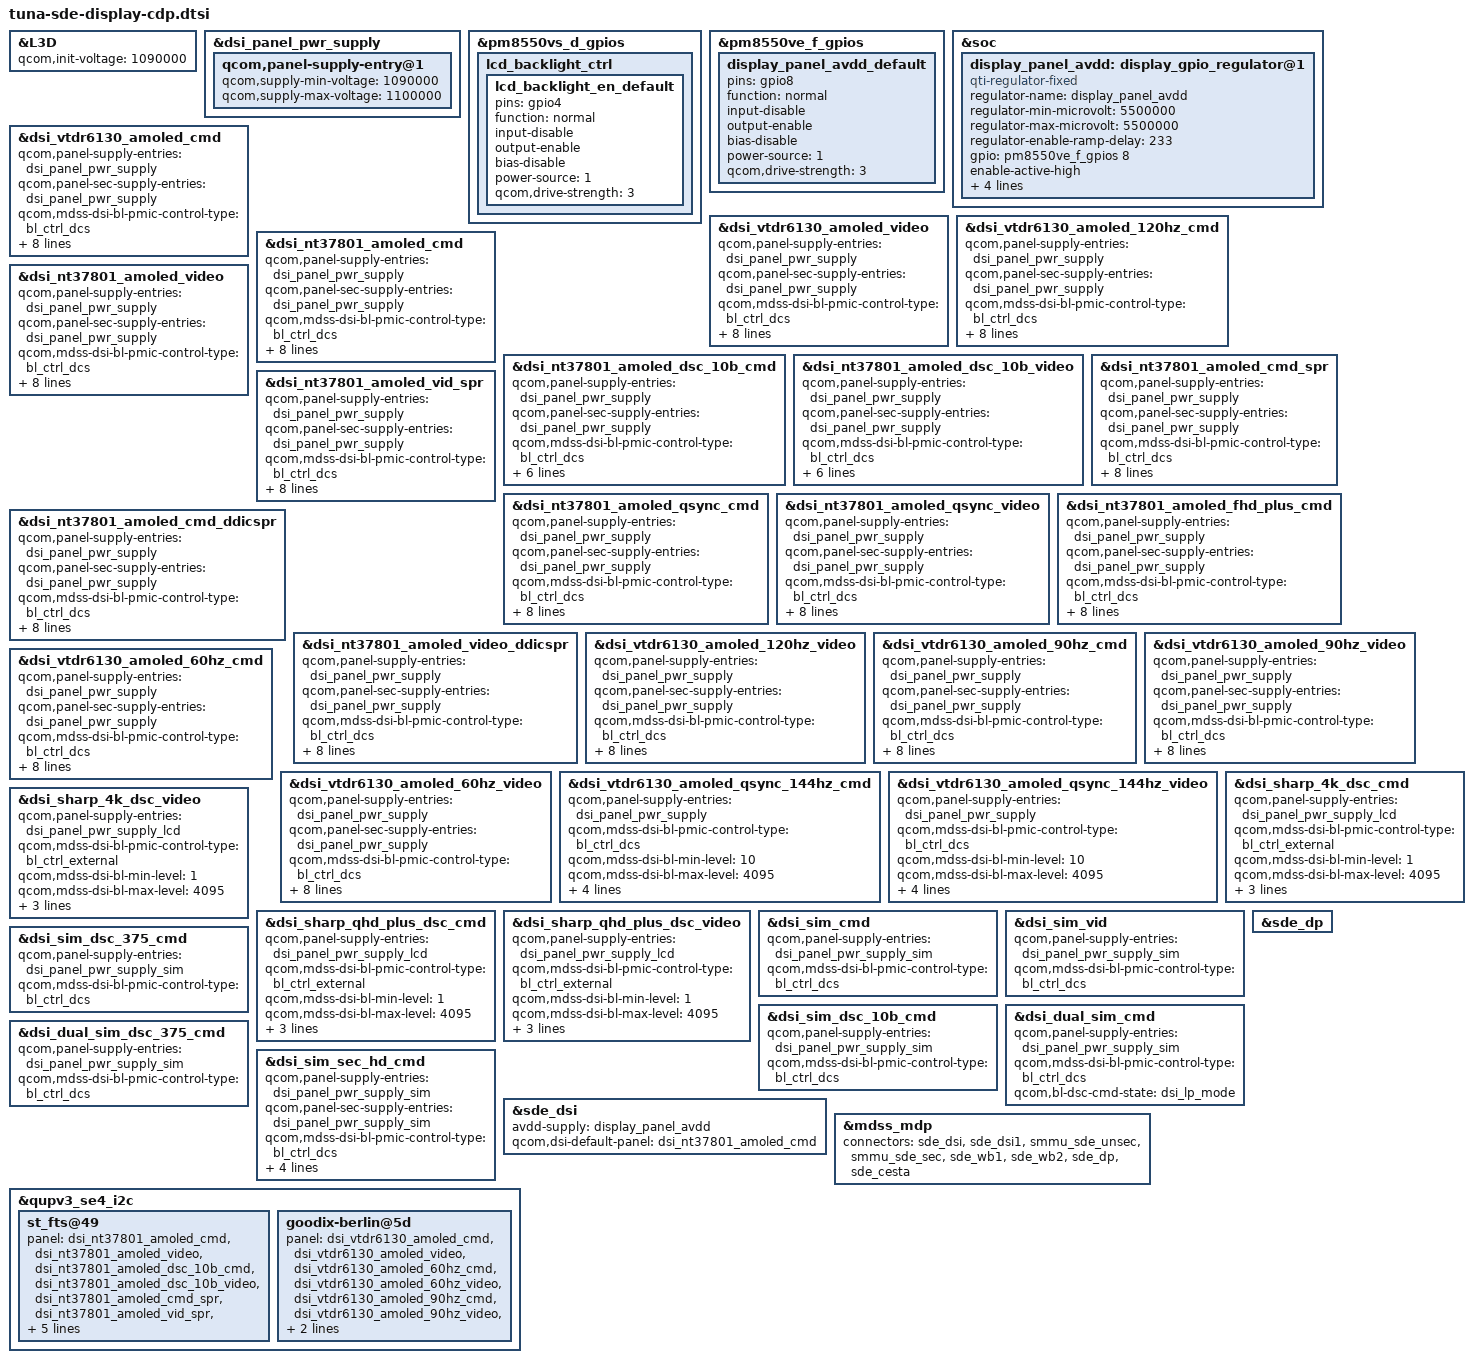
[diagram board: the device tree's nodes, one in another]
// SPDX-License-Identifier: BSD-3-Clause
/*
 * Copyright (c) Qualcomm Technologies, Inc. and/or its subsidiaries.
 */

#include "tuna-sde-display.dtsi"

&L3D {
	qcom,init-voltage = <1090000>;
};

&dsi_panel_pwr_supply {
	qcom,panel-supply-entry@1 {
		qcom,supply-min-voltage = <1090000>;
		qcom,supply-max-voltage = <1100000>;
	};
};

&pm8550vs_d_gpios {
	lcd_backlight_ctrl {
		lcd_backlight_en_default: lcd_backlight_en_default {
			pins = "gpio4";
			function = "normal";
			input-disable;
			output-enable;
			bias-disable;
			power-source = <1>;
			qcom,drive-strength = <3>;
		};
	};
};

&pm8550ve_f_gpios {
	display_panel_avdd_default: display_panel_avdd_default {
		pins = "gpio8";
		function = "normal";
		input-disable;
		output-enable;
		bias-disable;
		power-source = <1>;
		qcom,drive-strength = <3>;
	};
};

&soc {
	display_panel_avdd: display_gpio_regulator@1 {
		compatible = "qti-regulator-fixed";
		regulator-name = "display_panel_avdd";
		regulator-min-microvolt = <5500000>;
		regulator-max-microvolt = <5500000>;
		regulator-enable-ramp-delay = <233>;
		gpio = <&pm8550ve_f_gpios 8 0>;
		enable-active-high;
		regulator-boot-on;
		proxy-supply = <&display_panel_avdd>;
		qcom,proxy-consumer-enable;
		pinctrl-names = "default";
		pinctrl-0 = <&display_panel_avdd_default>;
	};
};

&dsi_vtdr6130_amoled_cmd {
	qcom,panel-supply-entries = <&dsi_panel_pwr_supply>;
	qcom,panel-sec-supply-entries = <&dsi_panel_pwr_supply>;
	qcom,mdss-dsi-bl-pmic-control-type = "bl_ctrl_dcs";
	qcom,mdss-dsi-sec-bl-pmic-control-type = "bl_ctrl_dcs";
	qcom,mdss-dsi-bl-min-level = <10>;
	qcom,mdss-dsi-bl-max-level = <4095>;
	qcom,mdss-brightness-max-level = <8191>;
	qcom,mdss-dsi-bl-inverted-dbv;
	qcom,platform-reset-gpio = <&tlmm 14 0>;
	qcom,platform-sec-reset-gpio = <&tlmm 126 0>;
};

&dsi_vtdr6130_amoled_video {
	qcom,panel-supply-entries = <&dsi_panel_pwr_supply>;
	qcom,panel-sec-supply-entries = <&dsi_panel_pwr_supply>;
	qcom,mdss-dsi-bl-pmic-control-type = "bl_ctrl_dcs";
	qcom,mdss-dsi-sec-bl-pmic-control-type = "bl_ctrl_dcs";
	qcom,mdss-dsi-bl-min-level = <10>;
	qcom,mdss-dsi-bl-max-level = <4095>;
	qcom,mdss-brightness-max-level = <8191>;
	qcom,mdss-dsi-bl-inverted-dbv;
	qcom,platform-reset-gpio = <&tlmm 14 0>;
	qcom,platform-sec-reset-gpio = <&tlmm 126 0>;
};

&dsi_vtdr6130_amoled_120hz_cmd {
	qcom,panel-supply-entries = <&dsi_panel_pwr_supply>;
	qcom,panel-sec-supply-entries = <&dsi_panel_pwr_supply>;
	qcom,mdss-dsi-bl-pmic-control-type = "bl_ctrl_dcs";
	qcom,mdss-dsi-sec-bl-pmic-control-type = "bl_ctrl_dcs";
	qcom,mdss-dsi-bl-min-level = <10>;
	qcom,mdss-dsi-bl-max-level = <4095>;
	qcom,mdss-brightness-max-level = <8191>;
	qcom,mdss-dsi-bl-inverted-dbv;
	qcom,platform-reset-gpio = <&tlmm 14 0>;
	qcom,platform-sec-reset-gpio = <&tlmm 126 0>;
};

&dsi_nt37801_amoled_cmd {
	qcom,panel-supply-entries = <&dsi_panel_pwr_supply>;
	qcom,panel-sec-supply-entries = <&dsi_panel_pwr_supply>;
	qcom,mdss-dsi-bl-pmic-control-type = "bl_ctrl_dcs";
	qcom,mdss-dsi-sec-bl-pmic-control-type = "bl_ctrl_dcs";
	qcom,mdss-dsi-bl-min-level = <10>;
	qcom,mdss-dsi-bl-max-level = <4095>;
	qcom,mdss-brightness-max-level = <8191>;
	qcom,mdss-dsi-bl-inverted-dbv;
	qcom,platform-reset-gpio = <&tlmm 14 0>;
	qcom,platform-sec-reset-gpio = <&tlmm 126 0>;
};

&dsi_nt37801_amoled_video {
	qcom,panel-supply-entries = <&dsi_panel_pwr_supply>;
	qcom,panel-sec-supply-entries = <&dsi_panel_pwr_supply>;
	qcom,mdss-dsi-bl-pmic-control-type = "bl_ctrl_dcs";
	qcom,mdss-dsi-sec-bl-pmic-control-type = "bl_ctrl_dcs";
	qcom,mdss-dsi-bl-min-level = <10>;
	qcom,mdss-dsi-bl-max-level = <4095>;
	qcom,mdss-brightness-max-level = <8191>;
	qcom,mdss-dsi-bl-inverted-dbv;
	qcom,platform-reset-gpio = <&tlmm 14 0>;
	qcom,platform-sec-reset-gpio = <&tlmm 126 0>;
};

&dsi_nt37801_amoled_dsc_10b_cmd {
	qcom,panel-supply-entries = <&dsi_panel_pwr_supply>;
	qcom,panel-sec-supply-entries = <&dsi_panel_pwr_supply>;
	qcom,mdss-dsi-bl-pmic-control-type = "bl_ctrl_dcs";
	qcom,mdss-dsi-bl-min-level = <10>;
	qcom,mdss-dsi-bl-max-level = <4095>;
	qcom,mdss-brightness-max-level = <8191>;
	qcom,mdss-dsi-bl-inverted-dbv;
	qcom,platform-reset-gpio = <&tlmm 14 0>;
	qcom,platform-sec-reset-gpio = <&tlmm 126 0>;
};

&dsi_nt37801_amoled_dsc_10b_video {
	qcom,panel-supply-entries = <&dsi_panel_pwr_supply>;
	qcom,panel-sec-supply-entries = <&dsi_panel_pwr_supply>;
	qcom,mdss-dsi-bl-pmic-control-type = "bl_ctrl_dcs";
	qcom,mdss-dsi-bl-min-level = <10>;
	qcom,mdss-dsi-bl-max-level = <4095>;
	qcom,mdss-brightness-max-level = <8191>;
	qcom,mdss-dsi-bl-inverted-dbv;
	qcom,platform-reset-gpio = <&tlmm 14 0>;
	qcom,platform-sec-reset-gpio = <&tlmm 126 0>;
};

&dsi_nt37801_amoled_cmd_spr {
	qcom,panel-supply-entries = <&dsi_panel_pwr_supply>;
	qcom,panel-sec-supply-entries = <&dsi_panel_pwr_supply>;
	qcom,mdss-dsi-bl-pmic-control-type = "bl_ctrl_dcs";
	qcom,mdss-dsi-sec-bl-pmic-control-type = "bl_ctrl_dcs";
	qcom,mdss-dsi-bl-min-level = <10>;
	qcom,mdss-dsi-bl-max-level = <4095>;
	qcom,mdss-brightness-max-level = <8191>;
	qcom,mdss-dsi-bl-inverted-dbv;
	qcom,platform-reset-gpio = <&tlmm 14 0>;
	qcom,platform-sec-reset-gpio = <&tlmm 126 0>;
};

&dsi_nt37801_amoled_vid_spr {
	qcom,panel-supply-entries = <&dsi_panel_pwr_supply>;
	qcom,panel-sec-supply-entries = <&dsi_panel_pwr_supply>;
	qcom,mdss-dsi-bl-pmic-control-type = "bl_ctrl_dcs";
	qcom,mdss-dsi-sec-bl-pmic-control-type = "bl_ctrl_dcs";
	qcom,mdss-dsi-bl-min-level = <10>;
	qcom,mdss-dsi-bl-max-level = <4095>;
	qcom,mdss-brightness-max-level = <8191>;
	qcom,mdss-dsi-bl-inverted-dbv;
	qcom,platform-reset-gpio = <&tlmm 14 0>;
	qcom,platform-sec-reset-gpio = <&tlmm 126 0>;
};

&dsi_nt37801_amoled_qsync_cmd {
	qcom,panel-supply-entries = <&dsi_panel_pwr_supply>;
	qcom,panel-sec-supply-entries = <&dsi_panel_pwr_supply>;
	qcom,mdss-dsi-bl-pmic-control-type = "bl_ctrl_dcs";
	qcom,mdss-dsi-sec-bl-pmic-control-type = "bl_ctrl_dcs";
	qcom,mdss-dsi-bl-min-level = <10>;
	qcom,mdss-dsi-bl-max-level = <4095>;
	qcom,mdss-brightness-max-level = <8191>;
	qcom,mdss-dsi-bl-inverted-dbv;
	qcom,platform-reset-gpio = <&tlmm 14 0>;
	qcom,platform-sec-reset-gpio = <&tlmm 126 0>;
};

&dsi_nt37801_amoled_qsync_video {
	qcom,panel-supply-entries = <&dsi_panel_pwr_supply>;
	qcom,panel-sec-supply-entries = <&dsi_panel_pwr_supply>;
	qcom,mdss-dsi-bl-pmic-control-type = "bl_ctrl_dcs";
	qcom,mdss-dsi-sec-bl-pmic-control-type = "bl_ctrl_dcs";
	qcom,mdss-dsi-bl-min-level = <10>;
	qcom,mdss-dsi-bl-max-level = <4095>;
	qcom,mdss-brightness-max-level = <8191>;
	qcom,mdss-dsi-bl-inverted-dbv;
	qcom,platform-reset-gpio = <&tlmm 14 0>;
	qcom,platform-sec-reset-gpio = <&tlmm 126 0>;
};

&dsi_nt37801_amoled_fhd_plus_cmd {
	qcom,panel-supply-entries = <&dsi_panel_pwr_supply>;
	qcom,panel-sec-supply-entries = <&dsi_panel_pwr_supply>;
	qcom,mdss-dsi-bl-pmic-control-type = "bl_ctrl_dcs";
	qcom,mdss-dsi-sec-bl-pmic-control-type = "bl_ctrl_dcs";
	qcom,mdss-dsi-bl-min-level = <10>;
	qcom,mdss-dsi-bl-max-level = <4095>;
	qcom,mdss-brightness-max-level = <8191>;
	qcom,mdss-dsi-bl-inverted-dbv;
	qcom,platform-reset-gpio = <&tlmm 14 0>;
	qcom,platform-sec-reset-gpio = <&tlmm 126 0>;
};

&dsi_nt37801_amoled_cmd_ddicspr {
	qcom,panel-supply-entries = <&dsi_panel_pwr_supply>;
	qcom,panel-sec-supply-entries = <&dsi_panel_pwr_supply>;
	qcom,mdss-dsi-bl-pmic-control-type = "bl_ctrl_dcs";
	qcom,mdss-dsi-sec-bl-pmic-control-type = "bl_ctrl_dcs";
	qcom,mdss-dsi-bl-min-level = <10>;
	qcom,mdss-dsi-bl-max-level = <4095>;
	qcom,mdss-brightness-max-level = <8191>;
	qcom,mdss-dsi-bl-inverted-dbv;
	qcom,platform-reset-gpio = <&tlmm 14 0>;
	qcom,platform-sec-reset-gpio = <&tlmm 126 0>;
};

&dsi_nt37801_amoled_video_ddicspr {
	qcom,panel-supply-entries = <&dsi_panel_pwr_supply>;
	qcom,panel-sec-supply-entries = <&dsi_panel_pwr_supply>;
	qcom,mdss-dsi-bl-pmic-control-type = "bl_ctrl_dcs";
	qcom,mdss-dsi-sec-bl-pmic-control-type = "bl_ctrl_dcs";
	qcom,mdss-dsi-bl-min-level = <10>;
	qcom,mdss-dsi-bl-max-level = <4095>;
	qcom,mdss-brightness-max-level = <8191>;
	qcom,mdss-dsi-bl-inverted-dbv;
	qcom,platform-reset-gpio = <&tlmm 14 0>;
	qcom,platform-sec-reset-gpio = <&tlmm 126 0>;
};

&dsi_vtdr6130_amoled_120hz_video {
	qcom,panel-supply-entries = <&dsi_panel_pwr_supply>;
	qcom,panel-sec-supply-entries = <&dsi_panel_pwr_supply>;
	qcom,mdss-dsi-bl-pmic-control-type = "bl_ctrl_dcs";
	qcom,mdss-dsi-sec-bl-pmic-control-type = "bl_ctrl_dcs";
	qcom,mdss-dsi-bl-min-level = <10>;
	qcom,mdss-dsi-bl-max-level = <4095>;
	qcom,mdss-brightness-max-level = <8191>;
	qcom,mdss-dsi-bl-inverted-dbv;
	qcom,platform-reset-gpio = <&tlmm 14 0>;
	qcom,platform-sec-reset-gpio = <&tlmm 126 0>;
};

&dsi_vtdr6130_amoled_90hz_cmd {
	qcom,panel-supply-entries = <&dsi_panel_pwr_supply>;
	qcom,panel-sec-supply-entries = <&dsi_panel_pwr_supply>;
	qcom,mdss-dsi-bl-pmic-control-type = "bl_ctrl_dcs";
	qcom,mdss-dsi-sec-bl-pmic-control-type = "bl_ctrl_dcs";
	qcom,mdss-dsi-bl-min-level = <10>;
	qcom,mdss-dsi-bl-max-level = <4095>;
	qcom,mdss-brightness-max-level = <8191>;
	qcom,mdss-dsi-bl-inverted-dbv;
	qcom,platform-reset-gpio = <&tlmm 14 0>;
	qcom,platform-sec-reset-gpio = <&tlmm 126 0>;
};

&dsi_vtdr6130_amoled_90hz_video {
	qcom,panel-supply-entries = <&dsi_panel_pwr_supply>;
	qcom,panel-sec-supply-entries = <&dsi_panel_pwr_supply>;
	qcom,mdss-dsi-bl-pmic-control-type = "bl_ctrl_dcs";
	qcom,mdss-dsi-sec-bl-pmic-control-type = "bl_ctrl_dcs";
	qcom,mdss-dsi-bl-min-level = <10>;
	qcom,mdss-dsi-bl-max-level = <4095>;
	qcom,mdss-brightness-max-level = <8191>;
	qcom,mdss-dsi-bl-inverted-dbv;
	qcom,platform-reset-gpio = <&tlmm 14 0>;
	qcom,platform-sec-reset-gpio = <&tlmm 126 0>;
};

&dsi_vtdr6130_amoled_60hz_cmd {
	qcom,panel-supply-entries = <&dsi_panel_pwr_supply>;
	qcom,panel-sec-supply-entries = <&dsi_panel_pwr_supply>;
	qcom,mdss-dsi-bl-pmic-control-type = "bl_ctrl_dcs";
	qcom,mdss-dsi-sec-bl-pmic-control-type = "bl_ctrl_dcs";
	qcom,mdss-dsi-bl-min-level = <10>;
	qcom,mdss-dsi-bl-max-level = <4095>;
	qcom,mdss-brightness-max-level = <8191>;
	qcom,mdss-dsi-bl-inverted-dbv;
	qcom,platform-reset-gpio = <&tlmm 14 0>;
	qcom,platform-sec-reset-gpio = <&tlmm 126 0>;
};

&dsi_vtdr6130_amoled_60hz_video {
	qcom,panel-supply-entries = <&dsi_panel_pwr_supply>;
	qcom,panel-sec-supply-entries = <&dsi_panel_pwr_supply>;
	qcom,mdss-dsi-bl-pmic-control-type = "bl_ctrl_dcs";
	qcom,mdss-dsi-sec-bl-pmic-control-type = "bl_ctrl_dcs";
	qcom,mdss-dsi-bl-min-level = <10>;
	qcom,mdss-dsi-bl-max-level = <4095>;
	qcom,mdss-brightness-max-level = <8191>;
	qcom,mdss-dsi-bl-inverted-dbv;
	qcom,platform-reset-gpio = <&tlmm 14 0>;
	qcom,platform-sec-reset-gpio = <&tlmm 126 0>;
};

&dsi_vtdr6130_amoled_qsync_144hz_cmd {
	qcom,panel-supply-entries = <&dsi_panel_pwr_supply>;
	qcom,mdss-dsi-bl-pmic-control-type = "bl_ctrl_dcs";
	qcom,mdss-dsi-bl-min-level = <10>;
	qcom,mdss-dsi-bl-max-level = <4095>;
	qcom,mdss-brightness-max-level = <8191>;
	qcom,mdss-dsi-bl-inverted-dbv;
	qcom,platform-reset-gpio = <&tlmm 14 0>;
	qcom,platform-sec-reset-gpio = <&tlmm 126 0>;
};

&dsi_vtdr6130_amoled_qsync_144hz_video {
	qcom,panel-supply-entries = <&dsi_panel_pwr_supply>;
	qcom,mdss-dsi-bl-pmic-control-type = "bl_ctrl_dcs";
	qcom,mdss-dsi-bl-min-level = <10>;
	qcom,mdss-dsi-bl-max-level = <4095>;
	qcom,mdss-brightness-max-level = <8191>;
	qcom,mdss-dsi-bl-inverted-dbv;
	qcom,platform-reset-gpio = <&tlmm 14 0>;
	qcom,platform-sec-reset-gpio = <&tlmm 126 0>;
};

&dsi_sharp_4k_dsc_cmd {
	qcom,panel-supply-entries = <&dsi_panel_pwr_supply_lcd>;
	qcom,mdss-dsi-bl-pmic-control-type = "bl_ctrl_external";
	qcom,mdss-dsi-bl-min-level = <1>;
	qcom,mdss-dsi-bl-max-level = <4095>;
	qcom,platform-reset-gpio = <&tlmm 14 0>;
	qcom,platform-bklight-en-gpio = <&pm8550vs_d_gpios 4 0>;
};

&dsi_sharp_4k_dsc_video {
	qcom,panel-supply-entries = <&dsi_panel_pwr_supply_lcd>;
	qcom,mdss-dsi-bl-pmic-control-type = "bl_ctrl_external";
	qcom,mdss-dsi-bl-min-level = <1>;
	qcom,mdss-dsi-bl-max-level = <4095>;
	qcom,platform-reset-gpio = <&tlmm 14 0>;
	qcom,platform-bklight-en-gpio = <&pm8550vs_d_gpios 4 0>;
};

&dsi_sharp_qhd_plus_dsc_cmd {
	qcom,panel-supply-entries = <&dsi_panel_pwr_supply_lcd>;
	qcom,mdss-dsi-bl-pmic-control-type = "bl_ctrl_external";
	qcom,mdss-dsi-bl-min-level = <1>;
	qcom,mdss-dsi-bl-max-level = <4095>;
	qcom,platform-reset-gpio = <&tlmm 14 0>;
	qcom,platform-bklight-en-gpio = <&pm8550vs_d_gpios 4 0>;
};

&dsi_sharp_qhd_plus_dsc_video {
	qcom,panel-supply-entries = <&dsi_panel_pwr_supply_lcd>;
	qcom,mdss-dsi-bl-pmic-control-type = "bl_ctrl_external";
	qcom,mdss-dsi-bl-min-level = <1>;
	qcom,mdss-dsi-bl-max-level = <4095>;
	qcom,platform-reset-gpio = <&tlmm 14 0>;
	qcom,platform-bklight-en-gpio = <&pm8550vs_d_gpios 4 0>;
};

&dsi_sim_cmd {
	qcom,panel-supply-entries = <&dsi_panel_pwr_supply_sim>;
	qcom,mdss-dsi-bl-pmic-control-type = "bl_ctrl_dcs";
};

&dsi_sim_vid {
	qcom,panel-supply-entries = <&dsi_panel_pwr_supply_sim>;
	qcom,mdss-dsi-bl-pmic-control-type = "bl_ctrl_dcs";
};

&dsi_sim_dsc_375_cmd {
	qcom,panel-supply-entries = <&dsi_panel_pwr_supply_sim>;
	qcom,mdss-dsi-bl-pmic-control-type = "bl_ctrl_dcs";
};

&dsi_sim_dsc_10b_cmd {
	qcom,panel-supply-entries = <&dsi_panel_pwr_supply_sim>;
	qcom,mdss-dsi-bl-pmic-control-type = "bl_ctrl_dcs";
};

&dsi_dual_sim_cmd {
	qcom,panel-supply-entries = <&dsi_panel_pwr_supply_sim>;
	qcom,mdss-dsi-bl-pmic-control-type = "bl_ctrl_dcs";
	qcom,bl-dsc-cmd-state = "dsi_lp_mode";
};

&dsi_dual_sim_dsc_375_cmd {
	qcom,panel-supply-entries = <&dsi_panel_pwr_supply_sim>;
	qcom,mdss-dsi-bl-pmic-control-type = "bl_ctrl_dcs";
};

&dsi_sim_sec_hd_cmd {
	qcom,panel-supply-entries = <&dsi_panel_pwr_supply_sim>;
	qcom,panel-sec-supply-entries = <&dsi_panel_pwr_supply_sim>;
	qcom,mdss-dsi-bl-pmic-control-type = "bl_ctrl_dcs";
	qcom,mdss-dsi-sec-bl-pmic-control-type = "bl_ctrl_dcs";
	qcom,mdss-dsi-bl-min-level = <1>;
	qcom,mdss-dsi-bl-max-level = <1023>;
};

&sde_dsi {
	avdd-supply = <&display_panel_avdd>;
	qcom,dsi-default-panel = <&dsi_nt37801_amoled_cmd>;
};

&sde_dp {
	status = "ok";
};

&mdss_mdp {
	connectors = <&sde_dsi &sde_dsi1 &smmu_sde_unsec &smmu_sde_sec &sde_wb1 &sde_wb2 &sde_dp
			&sde_cesta>;
};

&qupv3_se4_i2c {
	st_fts@49 {
		panel = <&dsi_nt37801_amoled_cmd
			&dsi_nt37801_amoled_video
			&dsi_nt37801_amoled_dsc_10b_cmd
			&dsi_nt37801_amoled_dsc_10b_video
			&dsi_nt37801_amoled_cmd_spr
			&dsi_nt37801_amoled_vid_spr
			&dsi_nt37801_amoled_qsync_cmd
			&dsi_nt37801_amoled_qsync_video
			&dsi_nt37801_amoled_fhd_plus_cmd
			&dsi_nt37801_amoled_cmd_ddicspr
			&dsi_nt37801_amoled_video_ddicspr>;
	};

	goodix-berlin@5d {
		panel = <&dsi_vtdr6130_amoled_cmd
			&dsi_vtdr6130_amoled_video
			&dsi_vtdr6130_amoled_60hz_cmd
			&dsi_vtdr6130_amoled_60hz_video
			&dsi_vtdr6130_amoled_90hz_cmd
			&dsi_vtdr6130_amoled_90hz_video
			&dsi_vtdr6130_amoled_120hz_cmd
			&dsi_vtdr6130_amoled_120hz_video>;
	};
};
